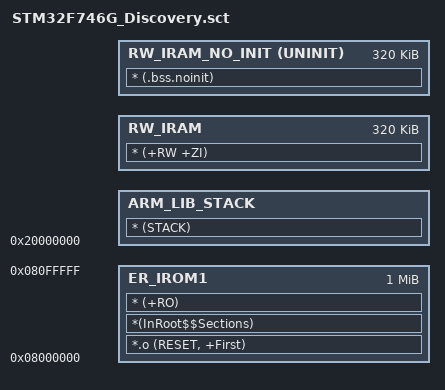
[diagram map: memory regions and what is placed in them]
; *************************************************************

; *** Scatter-Loading Description File generated by uVision ***

; *************************************************************


LR_IROM1 0x08000000 0x00100000  
{    
	; load region size_region
    
	ER_IROM1 0x08000000 0x00100000  
	{  
		; load address = execution address
    
		*.o (RESET, +First)
    
		*(InRoot$$Sections)
    
		* (+RO)
    
	}
    
    
	
	ARM_LIB_STACK 0x20000000   
	{
        
		* (STACK)
    
	}

    
    
	RW_IRAM +0 0x00050000  
	{  
		; RW data
        
		* (+RW +ZI)
    
	}

  
    
	RW_IRAM_NO_INIT +0 UNINIT 0x00050000 
	{
        
		* (.bss.noinit)
    
	}
    

}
